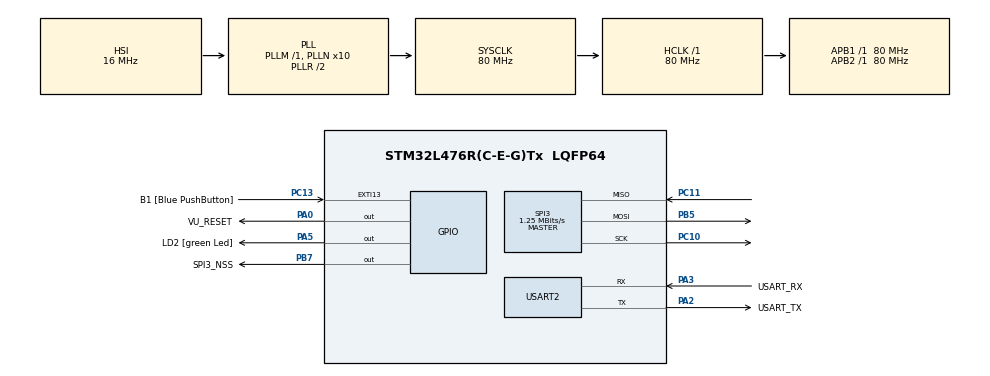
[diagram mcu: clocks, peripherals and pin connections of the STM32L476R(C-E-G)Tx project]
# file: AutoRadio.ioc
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FREERTOS.Tasks01=defaultTask,0,128,StartDefaultTask,Default,NULL,Dynamic,NULL,NULL
FREERTOS.configTOTAL_HEAP_SIZE=20000
FREERTOS.configUSE_NEWLIB_REENTRANT=1
Mcu.Family=STM32L4
Mcu.Name=STM32L476R(C-E-G)Tx
Mcu.Package=LQFP64
NVIC.PriorityGroup=NVIC_PRIORITYGROUP_4
NVIC.TIM1_TRG_COM_TIM17_IRQn=true\:15\:0\:false\:false\:true\:false\:false\:true\:true
NVIC.TimeBase=TIM1_TRG_COM_TIM17_IRQn
NVIC.TimeBaseIP=TIM17
NVIC.USART2_IRQn=true\:5\:0\:false\:false\:true\:true\:true\:true\:true
PA0.GPIO_Label=VU_RESET
PA0.PinState=GPIO_PIN_RESET
PA0.Signal=GPIO_Output
PA13\ (JTMS-SWDIO).GPIO_Label=TMS
PA13\ (JTMS-SWDIO).Mode=Serial_Wire
PA13\ (JTMS-SWDIO).Signal=SYS_JTMS-SWDIO
PA14\ (JTCK-SWCLK).GPIO_Label=TCK
PA14\ (JTCK-SWCLK).Mode=Serial_Wire
PA14\ (JTCK-SWCLK).Signal=SYS_JTCK-SWCLK
PA2.GPIO_Label=USART_TX
PA2.GPIO_Mode=GPIO_MODE_AF_PP
PA2.GPIO_PuPd=GPIO_NOPULL
PA2.GPIO_Speed=GPIO_SPEED_FREQ_VERY_HIGH
PA2.Mode=Asynchronous
PA2.Signal=USART2_TX
PA3.GPIO_Label=USART_RX
PA3.GPIO_Mode=GPIO_MODE_AF_PP
PA3.GPIO_PuPd=GPIO_NOPULL
PA3.GPIO_Speed=GPIO_SPEED_FREQ_VERY_HIGH
PA3.Mode=Asynchronous
PA3.Signal=USART2_RX
PA5.GPIO_Label=LD2 [green Led]
PA5.GPIO_ModeDefaultOutputPP=GPIO_MODE_OUTPUT_PP
PA5.GPIO_PuPd=GPIO_NOPULL
PA5.GPIO_Speed=GPIO_SPEED_FREQ_LOW
PA5.Signal=GPIO_Output
PB3\ (JTDO-TRACESWO).GPIO_Label=SWO
PB3\ (JTDO-TRACESWO).Signal=SYS_JTDO-SWO
PB5.Mode=Full_Duplex_Master
PB5.Signal=SPI3_MOSI
PB7.GPIO_Label=SPI3_NSS
PB7.PinState=GPIO_PIN_SET
PB7.Signal=GPIO_Output
PC10.Mode=Full_Duplex_Master
PC10.Signal=SPI3_SCK
PC11.Mode=Full_Duplex_Master
PC11.Signal=SPI3_MISO
PC13.GPIO_Label=B1 [Blue PushButton]
PC13.GPIO_ModeDefaultEXTI=GPIO_MODE_IT_FALLING
PC13.GPIO_PuPd=GPIO_NOPULL
PC13.Signal=GPXTI13
PC14-OSC32_IN\ (PC14).Signal=RCC_OSC32_IN
PC15-OSC32_OUT\ (PC15).Signal=RCC_OSC32_OUT
PH0-OSC_IN\ (PH0).Mode=HSE-External-Oscillator
PH0-OSC_IN\ (PH0).Signal=RCC_OSC_IN
PH1-OSC_OUT\ (PH1).Mode=HSE-External-Oscillator
PH1-OSC_OUT\ (PH1).Signal=RCC_OSC_OUT
ProjectManager.HeapSize=0x200
ProjectManager.StackSize=0x400
ProjectManager.TargetToolchain=STM32CubeIDE
RCC.ADCFreq_Value=64000000
RCC.AHBFreq_Value=80000000
RCC.APB1Freq_Value=80000000
RCC.APB1TimFreq_Value=80000000
RCC.APB2Freq_Value=80000000
RCC.APB2TimFreq_Value=80000000
RCC.CortexFreq_Value=80000000
RCC.HCLKFreq_Value=80000000
RCC.HSE_VALUE=8000000
RCC.HSI_VALUE=16000000
RCC.LSE_VALUE=32768
RCC.MSI_VALUE=4000000
RCC.PLLN=10
RCC.PLLSourceVirtual=RCC_PLLSOURCE_HSI
RCC.PREFETCH_ENABLE=1
RCC.SYSCLKFreq_VALUE=80000000
RCC.SYSCLKSource=RCC_SYSCLKSOURCE_PLLCLK
RCC.USBFreq_Value=64000000
RCC.VCOOutputFreq_Value=160000000
SPI3.BaudRatePrescaler=SPI_BAUDRATEPRESCALER_64
SPI3.CalculateBaudRate=1.25 MBits/s
SPI3.DataSize=SPI_DATASIZE_8BIT
SPI3.Direction=SPI_DIRECTION_2LINES
SPI3.Mode=SPI_MODE_MASTER
SPI3.VirtualType=VM_MASTER
USART2.VirtualMode-Asynchronous=VM_ASYNC
VP_FREERTOS_VS_CMSIS_V1.Mode=CMSIS_V1
VP_SYS_VS_tim17.Mode=TIM17
board=NUCLEO-L476RG

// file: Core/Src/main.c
/* USER CODE BEGIN Header */
/**
 ******************************************************************************
 * @file           : main.c
 * @brief          : Main program body
 ******************************************************************************
 * @attention
 *
 * Copyright (c) 2024 STMicroelectronics.
 * All rights reserved.
 *
 * This software is licensed under terms that can be found in the LICENSE file
 * in the root directory of this software component.
 * If no LICENSE file comes with this software, it is provided AS-IS.
 *
 ******************************************************************************
 */
/* USER CODE END Header */
#include "main.h"
#include "cmsis_os.h"
#include "spi.h"
#include "usart.h"
#include "gpio.h"

/* USER CODE BEGIN Includes */
#include "shell.h"
/* USER CODE END Includes */

/* USER CODE BEGIN PM */
#define TASK_STACK_DEPTH_SHELL 2048
#define TASK_PRIORITY_SHELL 4
/* USER CODE END PM */

/* USER CODE BEGIN PV */
TaskHandle_t h_task_shell = NULL;
/* USER CODE END PV */

void SystemClock_Config(void);
void MX_FREERTOS_Init(void);

int main(void)
{

  /* MCU Configuration--------------------------------------------------------*/

  /* Reset of all peripherals, Initializes the Flash interface and the Systick. */
  HAL_Init();

  /* Configure the system clock */
  SystemClock_Config();

  /* Initialize all configured peripherals */
  MX_GPIO_Init();
  MX_USART2_UART_Init();
  MX_SPI3_Init();
  /* USER CODE BEGIN 2 */
	shell_init();
	xTaskCreate(shell_run,	"Shell", TASK_STACK_DEPTH_SHELL, NULL, TASK_PRIORITY_SHELL, &h_task_shell) != pdPASS ? Error_Handler():(void)0;
	HAL_GPIO_WritePin(GPIOA, GPIO_PIN_0, GPIO_PIN_RESET);

  /* USER CODE END 2 */

  /* Call init function for freertos objects (in cmsis_os2.c) */
  MX_FREERTOS_Init();

  /* Start scheduler */
  osKernelStart();

  /* We should never get here as control is now taken by the scheduler */

  /* Infinite loop */
	while (1)
	{

	}
}

void SystemClock_Config(void)
{
  RCC_OscInitTypeDef RCC_OscInitStruct = {0};
  RCC_ClkInitTypeDef RCC_ClkInitStruct = {0};

  /** Configure the main internal regulator output voltage
  */
  if (HAL_PWREx_ControlVoltageScaling(PWR_REGULATOR_VOLTAGE_SCALE1) != HAL_OK)
  {
    Error_Handler();
  }

  /** Initializes the RCC Oscillators according to the specified parameters
  * in the RCC_OscInitTypeDef structure.
  */
  RCC_OscInitStruct.OscillatorType = RCC_OSCILLATORTYPE_HSI;
  RCC_OscInitStruct.HSIState = RCC_HSI_ON;
  RCC_OscInitStruct.HSICalibrationValue = RCC_HSICALIBRATION_DEFAULT;
  RCC_OscInitStruct.PLL.PLLState = RCC_PLL_ON;
  RCC_OscInitStruct.PLL.PLLSource = RCC_PLLSOURCE_HSI;
  RCC_OscInitStruct.PLL.PLLM = 1;
  RCC_OscInitStruct.PLL.PLLN = 10;
  RCC_OscInitStruct.PLL.PLLP = RCC_PLLP_DIV7;
  RCC_OscInitStruct.PLL.PLLQ = RCC_PLLQ_DIV2;
  RCC_OscInitStruct.PLL.PLLR = RCC_PLLR_DIV2;
  if (HAL_RCC_OscConfig(&RCC_OscInitStruct) != HAL_OK)
  {
    Error_Handler();
  }

  /** Initializes the CPU, AHB and APB buses clocks
  */
  RCC_ClkInitStruct.ClockType = RCC_CLOCKTYPE_HCLK|RCC_CLOCKTYPE_SYSCLK
                              |RCC_CLOCKTYPE_PCLK1|RCC_CLOCKTYPE_PCLK2;
  RCC_ClkInitStruct.SYSCLKSource = RCC_SYSCLKSOURCE_PLLCLK;
  RCC_ClkInitStruct.AHBCLKDivider = RCC_SYSCLK_DIV1;
  RCC_ClkInitStruct.APB1CLKDivider = RCC_HCLK_DIV1;
  RCC_ClkInitStruct.APB2CLKDivider = RCC_HCLK_DIV1;

  if (HAL_RCC_ClockConfig(&RCC_ClkInitStruct, FLASH_LATENCY_4) != HAL_OK)
  {
    Error_Handler();
  }
}

void HAL_TIM_PeriodElapsedCallback(TIM_HandleTypeDef *htim)
{
  if (htim->Instance == TIM17) {
    HAL_IncTick();
  }
}

void Error_Handler(void)
{
	__disable_irq();
	while (1)
	{
	}
}
